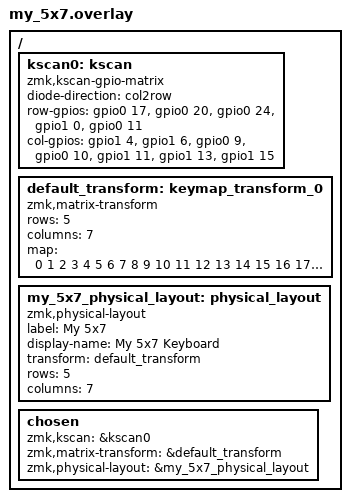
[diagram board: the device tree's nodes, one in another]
/ {
    kscan0: kscan {
        compatible = "zmk,kscan-gpio-matrix";
        diode-direction = "col2row";

        row-gpios = <&gpio0 17 (GPIO_ACTIVE_HIGH | GPIO_PULL_DOWN)>,
                    <&gpio0 20 (GPIO_ACTIVE_HIGH | GPIO_PULL_DOWN)>,
                    <&gpio0 24 (GPIO_ACTIVE_HIGH | GPIO_PULL_DOWN)>,
                    <&gpio1 0 (GPIO_ACTIVE_HIGH | GPIO_PULL_DOWN)>,
                    <&gpio0 11 (GPIO_ACTIVE_HIGH | GPIO_PULL_DOWN)>;

        col-gpios = <&gpio1 4 GPIO_ACTIVE_HIGH>,
                    <&gpio1 6 GPIO_ACTIVE_HIGH>,
                    <&gpio0 9 GPIO_ACTIVE_HIGH>,
                    <&gpio0 10 GPIO_ACTIVE_HIGH>,
                    <&gpio1 11 GPIO_ACTIVE_HIGH>,
                    <&gpio1 13 GPIO_ACTIVE_HIGH>,
                    <&gpio1 15 GPIO_ACTIVE_HIGH>;
    };

    default_transform: keymap_transform_0 {
        compatible = "zmk,matrix-transform";
        rows = <5>;
        columns = <7>;
        map = <
            0  1  2  3  4  5  6
            7  8  9  10 11 12 13
            14 15 16 17 18 19 20
            21 22 23 24 25 26 27
            28 29 30 31 32 33 34
        >;
    };

    my_5x7_physical_layout: physical_layout {
        compatible = "zmk,physical-layout";
        label = "My 5x7";
        display-name = "My 5x7 Keyboard";
        transform = <&default_transform>;
        rows = <5>;
        columns = <7>;
    };

    chosen {
        zmk,kscan = &kscan0;
        zmk,matrix-transform = &default_transform;
        zmk,physical-layout = &my_5x7_physical_layout;
    };
};
